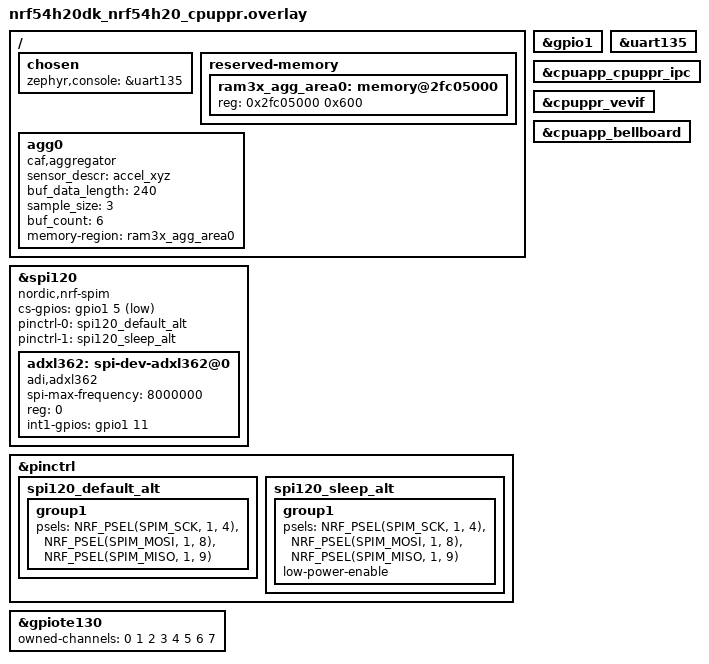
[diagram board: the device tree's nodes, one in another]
/*
 * Copyright (c) 2023 Nordic Semiconductor ASA
 *
 * SPDX-License-Identifier: LicenseRef-Nordic-5-Clause
 */

 / {
	chosen {
		zephyr,console = &uart135;
	};

	reserved-memory {
		ram3x_agg_area0: memory@2fc05000 {
			reg = <0x2fc05000 0x600>;
		};
	};

	agg0: agg0 {
		compatible = "caf,aggregator";
		sensor_descr = "accel_xyz";
		buf_data_length = <240>;
		sample_size = <3>;
		buf_count = <6>;
		memory-region = <&ram3x_agg_area0>;
		status = "okay";
	};
};

&spi120 {
	compatible = "nordic,nrf-spim";
	status = "okay";
	cs-gpios = <&gpio1 5 GPIO_ACTIVE_LOW>;

	pinctrl-0 = <&spi120_default_alt>;
	pinctrl-1 = <&spi120_sleep_alt>;
	pinctrl-names = "default", "sleep";
	adxl362: spi-dev-adxl362@0 {
		compatible = "adi,adxl362";
		spi-max-frequency = <8000000>;
		reg = <0>;
		int1-gpios = <&gpio1 11 0>;
	};
};

&pinctrl {
	spi120_default_alt: spi120_default_alt {
		group1 {
			psels = <NRF_PSEL(SPIM_SCK, 1, 4)>,
				<NRF_PSEL(SPIM_MOSI, 1, 8)>,
				<NRF_PSEL(SPIM_MISO, 1, 9)>;
		};
	};

	spi120_sleep_alt: spi120_sleep_alt {
		group1 {
			psels = <NRF_PSEL(SPIM_SCK, 1, 4)>,
				<NRF_PSEL(SPIM_MOSI, 1, 8)>,
				<NRF_PSEL(SPIM_MISO, 1, 9)>;
			low-power-enable;
		};
	};
};

&gpio1 {
	status = "okay";
};

&gpiote130 {
	owned-channels = <0 1 2 3 4 5 6 7>;
	status = "okay";
};

&uart135 {
	status = "okay";
};

// ipc0: &ipc_to_cpuapp {
// 	status = "okay";
// };

ipc0: &cpuapp_cpuppr_ipc {
	status = "okay";
};

&cpuppr_vevif {
	status = "okay";
};

&cpuapp_bellboard {
	status = "okay";
};
